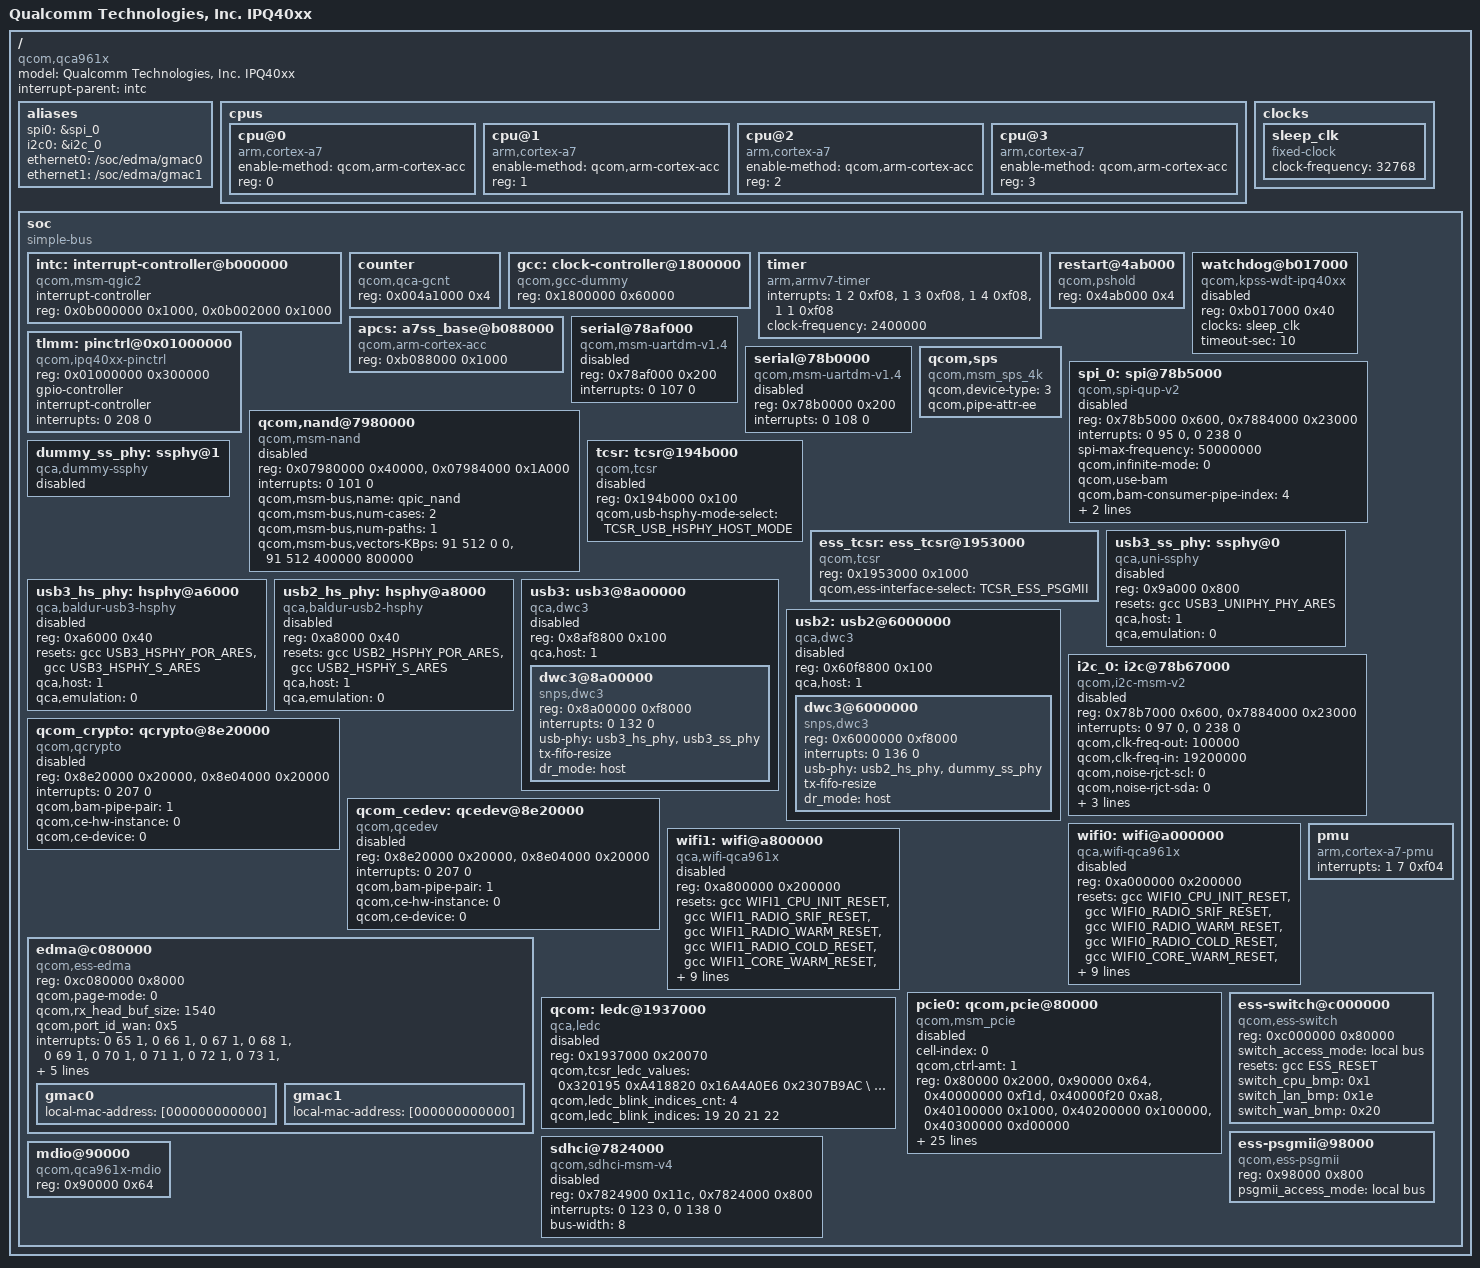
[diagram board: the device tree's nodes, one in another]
/*
 * Copyright (c) 2014, The Linux Foundation. All rights reserved.
 *
 * This program is free software; you can redistribute it and/or modify
 * it under the terms of the GNU General Public License version 2 and
 * only version 2 as published by the Free Software Foundation.
 *
 * This program is distributed in the hope that it will be useful,
 * but WITHOUT ANY WARRANTY; without even the implied warranty of
 * MERCHANTABILITY or FITNESS FOR A PARTICULAR PURPOSE.  See the
 * GNU General Public License for more details.
 */

/dts-v1/;

#include "skeleton.dtsi"
#include <dt-bindings/reset/qcom,gcc-ipq40xx.h>
#include <dt-bindings/clock/qcom,gcc-dummy.h>
#include <dt-bindings/soc/qcom,tcsr.h>
/ {
	model = "Qualcomm Technologies, Inc. IPQ40xx";
	compatible = "qcom,qca961x";
	interrupt-parent = <&intc>;

	aliases {
		spi0 = &spi_0;
		i2c0 = &i2c_0;
		ethernet0 = "/soc/edma/gmac0";
		ethernet1 = "/soc/edma/gmac1";
	};

	cpus {
		#address-cells = <1>;
		#size-cells = <0>;
		cpu@0 {
			device_type = "cpu";
			compatible = "arm,cortex-a7";
			enable-method = "qcom,arm-cortex-acc";
			reg = <0>;
		};

		cpu@1 {
			device_type = "cpu";
			compatible = "arm,cortex-a7";
			enable-method = "qcom,arm-cortex-acc";
			reg = <1>;
		};

		cpu@2 {
			device_type = "cpu";
			compatible = "arm,cortex-a7";
			enable-method = "qcom,arm-cortex-acc";
			reg = <2>;
		};

		cpu@3 {
			device_type = "cpu";
			compatible = "arm,cortex-a7";
			enable-method = "qcom,arm-cortex-acc";
			reg = <3>;
		};
	};

	clocks {
		sleep_clk: sleep_clk {
			compatible = "fixed-clock";
			clock-frequency = <32768>;
			#clock-cells = <0>;
		};
	};

	soc: soc { };
};

#include "qcom-ipq40xx-bus.dtsi"

	&soc {
		#address-cells = <1>;
		#size-cells = <1>;
		ranges;
		compatible = "simple-bus";

		intc: interrupt-controller@b000000 {
			compatible = "qcom,msm-qgic2";
			interrupt-controller;
			#interrupt-cells = <3>;
			reg = <0x0b000000 0x1000>,
			<0x0b002000 0x1000>;
		};

		counter {
			compatible = "qcom,qca-gcnt";
			reg = <0x004a1000 0x4>;
		};

		gcc: clock-controller@1800000 {
			compatible = "qcom,gcc-dummy";
			#clock-cells = <1>;
			#reset-cells = <1>;
			reg = <0x1800000 0x60000>;
		};

		timer {
			compatible = "arm,armv7-timer";
			interrupts = <1 2 0xf08>,
				     <1 3 0xf08>,
				     <1 4 0xf08>,
				     <1 1 0xf08>;
			clock-frequency = <2400000>;
		};

		restart@4ab000 {
			compatible = "qcom,pshold";
			reg = <0x4ab000 0x4>;
		};

		watchdog@b017000 {
			compatible = "qcom,kpss-wdt-ipq40xx";
			reg = <0xb017000 0x40>;
			clocks = <&sleep_clk>;
			timeout-sec = <10>;
			status = "disabled";
		};

		apcs: a7ss_base@b088000 {
			compatible = "qcom,arm-cortex-acc";
			reg = <0xb088000 0x1000>;
		};

		tlmm: pinctrl@0x01000000 {
			compatible = "qcom,ipq40xx-pinctrl";
			reg = <0x01000000 0x300000>;
			gpio-controller;
			#gpio-cells = <2>;
			interrupt-controller;
			#interrupt-cells = <2>;
			interrupts = <0 208 0>;
		};

		serial@78af000 {
			compatible = "qcom,msm-uartdm-v1.4", "qcom,msm-uartdm";
			reg = <0x78af000 0x200>;
			interrupts = <0 107 0>;
			status = "disabled";
		};

		serial@78b0000 {
			compatible = "qcom,msm-uartdm-v1.4", "qcom,msm-uartdm";
			reg = <0x78b0000 0x200>;
			interrupts = <0 108 0>;
			status = "disabled";
		};

		qcom,sps {
			compatible = "qcom,msm_sps_4k";
			qcom,device-type = <3>;
			qcom,pipe-attr-ee;
		};

		spi_0: spi@78b5000 { /* BLSP1 QUP1 */
			compatible = "qcom,spi-qup-v2";
			#address-cells = <1>;
			#size-cells = <0>;
			reg-names = "spi_physical", "spi_bam_physical";
			reg = <0x78b5000 0x600>,
				<0x7884000 0x23000>;
			interrupt-names = "spi_irq", "spi_bam_irq";
			interrupts = <0 95 0>, <0 238 0>;
			spi-max-frequency = <50000000>;
			qcom,infinite-mode = <0>;
			qcom,use-bam;
			qcom,bam-consumer-pipe-index = <4>;
			qcom,bam-producer-pipe-index = <5>;
			qcom,master-id = <0>;
			status = "disabled";
		};

		qcom,nand@7980000 {
			compatible = "qcom,msm-nand";
			reg = <0x07980000 0x40000>,
				<0x07984000 0x1A000>;
			reg-names = "nand_phys",
					"bam_phys";
			interrupts = <0 101 0>;
			interrupt-names = "bam_irq";

			qcom,msm-bus,name = "qpic_nand";
			qcom,msm-bus,num-cases = <2>;
			qcom,msm-bus,num-paths = <1>;

			qcom,msm-bus,vectors-KBps =
				<91 512 0 0>,
				/* Voting for max b/w on PNOC bus for now */
				<91 512 400000 800000>;
			status = "disabled";
		};

		tcsr: tcsr@194b000 {
			compatible = "qcom,tcsr";
			reg = <0x194b000 0x100>;
			qcom,usb-hsphy-mode-select = <TCSR_USB_HSPHY_HOST_MODE>;
			status = "disabled";
		};

		ess_tcsr: ess_tcsr@1953000 {
			compatible = "qcom,tcsr";
			reg = <0x1953000 0x1000>;
			qcom,ess-interface-select = <TCSR_ESS_PSGMII>;
		};

		usb3_ss_phy: ssphy@0 {
			compatible = "qca,uni-ssphy";
			reg = <0x9a000 0x800>;
			reg-names = "phy_base";
			resets = <&gcc USB3_UNIPHY_PHY_ARES>;
			reset-names = "por_rst";
			qca,host = <1>;
			qca,emulation = <0>;
			status = "disabled";
		};

		dummy_ss_phy: ssphy@1 {
			compatible = "qca,dummy-ssphy";
			status = "disabled";
		};

		usb3_hs_phy: hsphy@a6000 {
			compatible = "qca,baldur-usb3-hsphy";
			reg = <0xa6000 0x40>;
			reg-names = "phy_base";
			resets = <&gcc USB3_HSPHY_POR_ARES>, <&gcc USB3_HSPHY_S_ARES>;
			reset-names = "por_rst", "srif_rst";
			qca,host = <1>;
			qca,emulation = <0>;
			status = "disabled";
		};

		usb2_hs_phy: hsphy@a8000 {
			compatible = "qca,baldur-usb2-hsphy";
			reg = <0xa8000 0x40>;
			reg-names = "phy_base";
			resets = <&gcc USB2_HSPHY_POR_ARES>, <&gcc USB2_HSPHY_S_ARES>;
			reset-names = "por_rst", "srif_rst";
			qca,host = <1>;
			qca,emulation = <0>;
			status = "disabled";
		};

		usb3: usb3@8a00000 {
			compatible = "qca,dwc3";
			#address-cells = <1>;
			#size-cells = <1>;
			ranges;
			reg = <0x8af8800 0x100>;
			reg-names = "qscratch_base";
			qca,host = <1>;
			status = "disabled";

			dwc3@8a00000 {
				compatible = "snps,dwc3";
				reg = <0x8a00000 0xf8000>;
				interrupts = <0 132 0>;
				usb-phy = <&usb3_hs_phy>, <&usb3_ss_phy>;
				phy-names = "usb2-phy", "usb3-phy";
				tx-fifo-resize;
				dr_mode = "host";
			};
		};

		usb2: usb2@6000000 {
			compatible = "qca,dwc3";
			#address-cells = <1>;
			#size-cells = <1>;
			ranges;
			reg = <0x60f8800 0x100>;
			reg-names = "qscratch_base";
			qca,host = <1>;
			status = "disabled";

			dwc3@6000000 {
				compatible = "snps,dwc3";
				reg = <0x6000000 0xf8000>;
				interrupts = <0 136 0>;
				usb-phy = <&usb2_hs_phy>, <&dummy_ss_phy>;
				phy-names = "usb2-phy", "usb3-phy";
				tx-fifo-resize;
				dr_mode = "host";
			};
		};

		i2c_0: i2c@78b67000 { /* BLSP1 QUP2 */
			compatible = "qcom,i2c-msm-v2";
			#address-cells = <1>;
			#size-cells = <0>;
			reg-names = "qup_phys_addr", "bam_phys_addr";
			reg = <0x78b7000 0x600>,
				<0x7884000 0x23000>;
			interrupt-names = "qup_irq", "bam_irq";
			interrupts = <0 97 0>, <0 238 0>;
			qcom,clk-freq-out = <100000>;
			qcom,clk-freq-in  = <19200000>;
			qcom,noise-rjct-scl = <0>;
			qcom,noise-rjct-sda = <0>;
			qcom,bam-pipe-idx-cons = <8>;
			qcom,bam-pipe-idx-prod = <9>;
			qcom,master-id = <0>;
			status = "disabled";
		};

		qcom_crypto: qcrypto@8e20000 {
			compatible = "qcom,qcrypto";
			reg = <0x8e20000 0x20000>,
				<0x8e04000 0x20000>;
			reg-names = "crypto-base","crypto-bam-base";
			interrupts = <0 207 0>;
			qcom,bam-pipe-pair = <1>;
			qcom,ce-hw-instance = <0>;
			qcom,ce-device = <0>;
			status = "disabled";
		};

		qcom_cedev: qcedev@8e20000 {
			compatible = "qcom,qcedev";
			reg = <0x8e20000  0x20000>,
				<0x8e04000  0x20000>;
			reg-names = "crypto-base","crypto-bam-base";
			interrupts = <0 207 0>;
			qcom,bam-pipe-pair = <1>;
			qcom,ce-hw-instance = <0>;
			qcom,ce-device = <0>;
			status = "disabled";
		};

		wifi0: wifi@a000000 {
			compatible = "qca,wifi-qca961x";
			reg = <0xa000000 0x200000>;
			resets = <&gcc WIFI0_CPU_INIT_RESET>,
				<&gcc WIFI0_RADIO_SRIF_RESET>,
				<&gcc WIFI0_RADIO_WARM_RESET>,
				<&gcc WIFI0_RADIO_COLD_RESET>,
				<&gcc WIFI0_CORE_WARM_RESET>,
				<&gcc WIFI0_CORE_COLD_RESET>;
			reset-names = "wifi_cpu_init",
				"wifi_radio_srif",
				"wifi_radio_warm",
				"wifi_radio_cold",
				"wifi_core_warm",
				"wifi_core_cold";
			/* TBD: Check if 'clocks' entry is required here - if required, add the entries once they are defined in GCC driver */
			interrupts = <0 0x20 0x1>,
				<0 0x21 0x1>,
				<0 0x22 0x1>,
				<0 0x23 0x1>,
				<0 0x24 0x1>,
				<0 0x25 0x1>,
				<0 0x26 0x1>,
				<0 0x27 0x1>,
				<0 0x28 0x1>,
				<0 0x29 0x1>,
				<0 0x2a 0x1>,
				<0 0x2b 0x1>,
				<0 0x2c 0x1>,
				<0 0x2d 0x1>,
				<0 0x2e 0x1>,
				<0 0x2f 0x1>,
				<0 0xa8 0x0>;
			interrupt-names = "msi0", "msi1", "msi2", "msi3", "msi4", "msi5", "msi6",
				"msi7", "msi8", "msi9", "msi10", "msi11", "msi12", "msi13", "msi14",
				"msi15", "legacy";
			status = "disabled";
			qca,msi_addr = <0x0b006040>;
			qca,msi_base = <0x40>;
		};

		wifi1: wifi@a800000 {
			compatible = "qca,wifi-qca961x";
			reg = <0xa800000 0x200000>;
			resets = <&gcc WIFI1_CPU_INIT_RESET>,
				<&gcc WIFI1_RADIO_SRIF_RESET>,
				<&gcc WIFI1_RADIO_WARM_RESET>,
				<&gcc WIFI1_RADIO_COLD_RESET>,
				<&gcc WIFI1_CORE_WARM_RESET>,
				<&gcc WIFI1_CORE_COLD_RESET>;
			reset-names = "wifi_cpu_init",
				"wifi_radio_srif",
				"wifi_radio_warm",
				"wifi_radio_cold",
				"wifi_core_warm",
				"wifi_core_cold";
			/* TBD: Check if 'clocks' entry is required here - if required, add the entries once they are defined in GCC driver */
			interrupts = <0 0x30 0x1>,
				<0 0x31 0x1>,
				<0 0x32 0x1>,
				<0 0x33 0x1>,
				<0 0x34 0x1>,
				<0 0x35 0x1>,
				<0 0x36 0x1>,
				<0 0x37 0x1>,
				<0 0x38 0x1>,
				<0 0x39 0x1>,
				<0 0x3a 0x1>,
				<0 0x3b 0x1>,
				<0 0x3c 0x1>,
				<0 0x3d 0x1>,
				<0 0x3e 0x1>,
				<0 0x3f 0x1>,
				<0 0xa9 0x0>;
			interrupt-names = "msi0", "msi1", "msi2", "msi3", "msi4", "msi5", "msi6",
				"msi7", "msi8", "msi9", "msi10", "msi11", "msi12", "msi13", "msi14",
				"msi15", "legacy";
			status = "disabled";
			qca,msi_addr = <0x0b006040>;
			qca,msi_base = <0x50>;
		};

		edma@c080000 {
			compatible = "qcom,ess-edma";
			reg = <0xc080000 0x8000>;
			qcom,page-mode = <0>;
			qcom,rx_head_buf_size = <1540>;
			qcom,port_id_wan = <0x5>;
			interrupts = <0 65 1>,
					<0 66 1>,
					<0 67 1>,
					<0 68 1>,
					<0 69 1>,
					<0 70 1>,
					<0 71 1>,
					<0 72 1>,
					<0 73 1>,
					<0 74 1>,
					<0 75 1>,
					<0 76 1>,
					<0 77 1>,
					<0 78 1>,
					<0 79 1>,
					<0 80 1>,
					<0 240 1>,
					<0 241 1>,
					<0 242 1>,
					<0 243 1>,
					<0 244 1>,
					<0 245 1>,
					<0 246 1>,
					<0 247 1>,
					<0 248 1>,
					<0 249 1>,
					<0 250 1>,
					<0 251 1>,
					<0 252 1>,
					<0 253 1>,
					<0 254 1>,
					<0 255 1>;
			gmac0 {
				local-mac-address = [000000000000];
			};
			gmac1 {
				local-mac-address = [000000000000];
			};
		};

		pcie0: qcom,pcie@80000 {
			compatible = "qcom,msm_pcie";
			cell-index = <0>;
			qcom,ctrl-amt = <1>;

			reg = <0x80000 0x2000>,
			      <0x90000 0x64>,
			      <0x40000000 0xf1d>,
			      <0x40000f20 0xa8>,
			      <0x40100000 0x1000>,
			      <0x40200000 0x100000>,
			      <0x40300000 0xd00000>;
			reg-names = "parf", "phy", "dm_core", "elbi",
				"conf", "io", "bars";

			#address-cells = <0>;
			interrupt-parent = <&pcie0>;
			interrupts = <0 1 2 3 4 5 6 7 8 9 10 11 12>;
			#interrupt-cells = <1>;
			interrupt-map-mask = <0xffffffff>;
			interrupt-map = <0 &intc 0 141 0
				1 &intc 0 142 0
				2 &intc 0 143 0
				3 &intc 0 144 0
				4 &intc 0 145 0
				5 &intc 0 146 0
				6 &intc 0 147 0
				7 &intc 0 148 0
				8 &intc 0 149 0
				9 &intc 0 150 0
				10 &intc 0 151 0
				11 &intc 0 152 0 >;

			interrupt-names = "int_msi", "int_a", "int_b", "int_c", "int_d",
				"int_pls_pme", "int_pme_legacy", "int_pls_err",
				"int_aer_legacy", "int_pls_link_up",
				"int_pls_link_down", "int_bridge_flush_n","int_wake";

			qcom,ep-latency = <10>;
			perst-gpio = <&tlmm 61 0>;
			wake-gpio = <&tlmm 65 0>;
			clkreq-gpio = <&tlmm 64 0>;

			max-clock-frequency-hz = <125000000>, <0>, <1011000>, <0>, <0>, <0>, <0>, <0>;

			resets = <&gcc PCIE_AXI_M_ARES>,
				<&gcc PCIE_AXI_S_ARES>,
				<&gcc PCIE_PIPE_ARES>,
				<&gcc PCIE_AXI_M_VMIDMT_ARES>,
				<&gcc PCIE_AXI_S_XPU_ARES>,
				<&gcc PCIE_PARF_XPU_ARES>,
				<&gcc PCIE_PHY_ARES>,
				<&gcc PCIE_AXI_M_STICKY_ARES>,
				<&gcc PCIE_PIPE_STICKY_ARES>,
				<&gcc PCIE_PWR_ARES>,
				<&gcc PCIE_AHB_ARES>,
				<&gcc PCIE_PHY_AHB_ARES>;

			reset-names = "pcie_rst_axi_m_ares",
				"pcie_rst_axi_s_ares",
				"pcie_rst_pipe_ares",
				"pcie_rst_axi_m_vmidmt_ares",
				"pcie_rst_axi_s_xpu_ares",
				"pcie_rst_parf_xpu_ares",
				"pcie_rst_phy_ares",
				"pcie_rst_axi_m_sticky_ares",
				"pcie_rst_pipe_sticky_ares",
				"pcie_rst_pwr_ares",
				"pcie_rst_ahb_res",
				"pcie_rst_phy_ahb_ares";
			status = "disabled";
		};

		qcom: ledc@1937000  {
			compatible = "qca,ledc";
			reg = <0x1937000 0x20070>;
			reg-names = "ledc_base_addr";
			qcom,tcsr_ledc_values = <0x320195 0xA418820 0x16A4A0E6 0x2307B9AC \
				0x16AD272 0xFFFFFFFF 0x0 0x0 0x7D006F 0x0 0x10482090 0x3FFFFE4>;
			qcom,ledc_blink_indices_cnt = <4>;
			qcom,ledc_blink_indices = <19 20 21 22>;
			status = "disabled";
		};

		pmu {
			compatible = "arm,cortex-a7-pmu";
			interrupts = <1 7 0xf04>;
		};

		sdhci@7824000 {
			compatible = "qcom,sdhci-msm-v4";
			reg = <0x7824900 0x11c>, <0x7824000 0x800>;
			interrupts = <0 123 0>, <0 138 0>;
			bus-width = <8>;
			status = "disabled";
		};

		ess-switch@c000000 {
			compatible = "qcom,ess-switch";
			reg = <0xc000000 0x80000>; /* 512KB */
			switch_access_mode = "local bus";
			resets = <&gcc ESS_RESET>;
			switch_cpu_bmp = <0x1>;  /* cpu port bitmap */
			switch_lan_bmp = <0x1e>; /* lan port bitmap */
			switch_wan_bmp = <0x20>; /* wan port bitmap */
		};
		ess-psgmii@98000 {
			compatible = "qcom,ess-psgmii";
			reg = <0x98000 0x800>; /* 2k */
			psgmii_access_mode = "local bus";
		};

		mdio@90000 {
			#address-cells = <1>;
			#size-cells = <1>;
			compatible = "qcom,qca961x-mdio";
			reg = <0x90000 0x64>;
		};

	};
